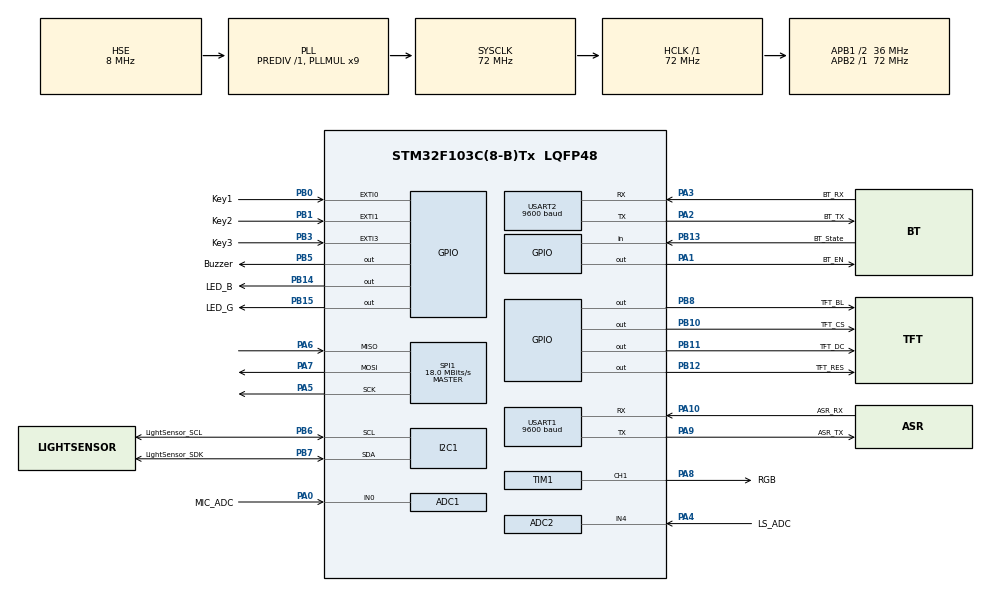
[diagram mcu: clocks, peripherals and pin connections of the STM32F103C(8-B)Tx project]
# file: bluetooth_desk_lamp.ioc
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ADC1.Channel-0\#ChannelRegularConversion=ADC_CHANNEL_0
ADC1.ContinuousConvMode=DISABLE
ADC1.ExternalTrigConv=ADC_EXTERNALTRIGCONV_T3_TRGO
ADC1.NbrOfConversion=1
ADC1.NbrOfConversionFlag=1
ADC1.Rank-0\#ChannelRegularConversion=1
ADC1.SamplingTime-0\#ChannelRegularConversion=ADC_SAMPLETIME_239CYCLES_5
ADC1.master=1
ADC2.Channel-0\#ChannelRegularConversion=ADC_CHANNEL_4
ADC2.ContinuousConvMode=ENABLE
ADC2.NbrOfConversionFlag=1
ADC2.Rank-0\#ChannelRegularConversion=1
ADC2.SamplingTime-0\#ChannelRegularConversion=ADC_SAMPLETIME_1CYCLE_5
Dma.ADC1.0.Direction=DMA_PERIPH_TO_MEMORY
Dma.ADC1.0.Instance=DMA1_Channel1
Dma.ADC1.0.MemDataAlignment=DMA_MDATAALIGN_HALFWORD
Dma.ADC1.0.MemInc=DMA_MINC_ENABLE
Dma.ADC1.0.Mode=DMA_CIRCULAR
Dma.ADC1.0.PeriphDataAlignment=DMA_PDATAALIGN_HALFWORD
Dma.ADC1.0.PeriphInc=DMA_PINC_DISABLE
Dma.ADC1.0.Priority=DMA_PRIORITY_MEDIUM
Dma.Request0=ADC1
Dma.Request1=USART1_RX
Dma.Request2=USART1_TX
Dma.Request3=TIM1_CH1
Dma.TIM1_CH1.3.Direction=DMA_MEMORY_TO_PERIPH
Dma.TIM1_CH1.3.Instance=DMA1_Channel2
Dma.TIM1_CH1.3.MemDataAlignment=DMA_MDATAALIGN_HALFWORD
Dma.TIM1_CH1.3.MemInc=DMA_MINC_ENABLE
Dma.TIM1_CH1.3.Mode=DMA_NORMAL
Dma.TIM1_CH1.3.PeriphDataAlignment=DMA_PDATAALIGN_HALFWORD
Dma.TIM1_CH1.3.PeriphInc=DMA_PINC_DISABLE
Dma.TIM1_CH1.3.Priority=DMA_PRIORITY_LOW
Dma.USART1_RX.1.Direction=DMA_PERIPH_TO_MEMORY
Dma.USART1_RX.1.Instance=DMA1_Channel5
Dma.USART1_RX.1.MemDataAlignment=DMA_MDATAALIGN_BYTE
Dma.USART1_RX.1.MemInc=DMA_MINC_ENABLE
Dma.USART1_RX.1.Mode=DMA_CIRCULAR
Dma.USART1_RX.1.PeriphDataAlignment=DMA_PDATAALIGN_BYTE
Dma.USART1_RX.1.PeriphInc=DMA_PINC_DISABLE
Dma.USART1_RX.1.Priority=DMA_PRIORITY_HIGH
Dma.USART1_TX.2.Direction=DMA_MEMORY_TO_PERIPH
Dma.USART1_TX.2.Instance=DMA1_Channel4
Dma.USART1_TX.2.MemDataAlignment=DMA_MDATAALIGN_BYTE
Dma.USART1_TX.2.MemInc=DMA_MINC_ENABLE
Dma.USART1_TX.2.Mode=DMA_NORMAL
Dma.USART1_TX.2.PeriphDataAlignment=DMA_PDATAALIGN_BYTE
Dma.USART1_TX.2.PeriphInc=DMA_PINC_DISABLE
Dma.USART1_TX.2.Priority=DMA_PRIORITY_MEDIUM
Mcu.Family=STM32F1
Mcu.Name=STM32F103C(8-B)Tx
Mcu.Package=LQFP48
NVIC.DMA1_Channel1_IRQn=true\:0\:0\:false\:false\:true\:false\:true\:true
NVIC.DMA1_Channel2_IRQn=true\:0\:0\:false\:false\:true\:false\:true\:true
NVIC.DMA1_Channel4_IRQn=true\:0\:0\:false\:false\:true\:false\:true\:true
NVIC.DMA1_Channel5_IRQn=true\:0\:0\:false\:false\:true\:false\:true\:true
NVIC.EXTI0_IRQn=true\:0\:0\:false\:false\:true\:true\:true\:true
NVIC.EXTI1_IRQn=true\:0\:0\:false\:false\:true\:true\:true\:true
NVIC.EXTI3_IRQn=true\:0\:0\:false\:false\:true\:true\:true\:true
NVIC.PriorityGroup=NVIC_PRIORITYGROUP_4
NVIC.USART1_IRQn=true\:0\:0\:false\:false\:true\:true\:true\:true
NVIC.USART2_IRQn=true\:0\:0\:false\:false\:true\:true\:true\:true
PA0-WKUP.GPIO_Label=MIC_ADC
PA0-WKUP.Signal=ADCx_IN0
PA1.GPIO_Label=BT_EN
PA1.Signal=GPIO_Output
PA10.GPIO_Label=ASR_RX
PA10.Mode=Asynchronous
PA10.Signal=USART1_RX
PA13.Mode=Serial_Wire
PA13.Signal=SYS_JTMS-SWDIO
PA14.Mode=Serial_Wire
PA14.Signal=SYS_JTCK-SWCLK
PA2.GPIO_Label=BT_TX
PA2.Mode=Asynchronous
PA2.Signal=USART2_TX
PA3.GPIO_Label=BT_RX
PA3.Mode=Asynchronous
PA3.Signal=USART2_RX
PA4.GPIO_Label=LS_ADC
PA4.Signal=ADCx_IN4
PA5.Mode=Full_Duplex_Master
PA5.Signal=SPI1_SCK
PA6.Mode=Full_Duplex_Master
PA6.Signal=SPI1_MISO
PA7.Mode=Full_Duplex_Master
PA7.Signal=SPI1_MOSI
PA8.GPIO_Label=RGB
PA8.Signal=S_TIM1_CH1
PA9.GPIO_Label=ASR_TX
PA9.Mode=Asynchronous
PA9.Signal=USART1_TX
PB0.GPIO_Label=Key1
PB0.GPIO_ModeDefaultEXTI=GPIO_MODE_IT_FALLING
PB0.GPIO_PuPd=GPIO_PULLUP
PB0.Signal=GPXTI0
PB1.GPIO_Label=Key2
PB1.GPIO_ModeDefaultEXTI=GPIO_MODE_IT_FALLING
PB1.GPIO_PuPd=GPIO_PULLUP
PB1.Signal=GPXTI1
PB10.GPIO_Label=TFT_CS
PB10.PinState=GPIO_PIN_SET
PB10.Signal=GPIO_Output
PB11.GPIO_Label=TFT_DC
PB11.Signal=GPIO_Output
PB12.GPIO_Label=TFT_RES
PB12.PinState=GPIO_PIN_SET
PB12.Signal=GPIO_Output
PB13.GPIO_Label=BT_State
PB13.Signal=GPIO_Input
PB14.GPIO_Label=LED_B
PB14.Signal=GPIO_Output
PB15.GPIO_Label=LED_G
PB15.Signal=GPIO_Output
PB3.GPIO_Label=Key3
PB3.GPIO_ModeDefaultEXTI=GPIO_MODE_IT_FALLING
PB3.GPIO_PuPd=GPIO_PULLUP
PB3.Signal=GPXTI3
PB5.GPIO_Label=Buzzer
PB5.Signal=GPIO_Output
PB6.GPIO_Label=LightSensor_SCL
PB6.Mode=I2C
PB6.Signal=I2C1_SCL
PB7.GPIO_Label=LightSensor_SDK
PB7.Mode=I2C
PB7.Signal=I2C1_SDA
PB8.GPIO_Label=TFT_BL
PB8.Signal=GPIO_Output
PD0-OSC_IN.Mode=HSE-External-Oscillator
PD0-OSC_IN.Signal=RCC_OSC_IN
PD1-OSC_OUT.Mode=HSE-External-Oscillator
PD1-OSC_OUT.Signal=RCC_OSC_OUT
ProjectManager.HeapSize=0x200
ProjectManager.StackSize=0x400
ProjectManager.TargetToolchain=MDK-ARM V5.32
RCC.ADCPresc=RCC_ADCPCLK2_DIV6
RCC.AHBFreq_Value=72000000
RCC.APB1CLKDivider=RCC_HCLK_DIV2
RCC.APB1Freq_Value=36000000
RCC.APB1TimFreq_Value=72000000
RCC.APB2Freq_Value=72000000
RCC.APB2TimFreq_Value=72000000
RCC.HCLKFreq_Value=72000000
RCC.PLLMUL=RCC_PLL_MUL9
RCC.PLLSourceVirtual=RCC_PLLSOURCE_HSE
RCC.SYSCLKFreq_VALUE=72000000
RCC.SYSCLKSource=RCC_SYSCLKSOURCE_PLLCLK
RCC.USBFreq_Value=72000000
SH.ADCx_IN0.0=ADC1_IN0,IN0
SH.ADCx_IN4.0=ADC2_IN4,IN4
SH.S_TIM1_CH1.0=TIM1_CH1,PWM Generation1 CH1
SPI1.BaudRatePrescaler=SPI_BAUDRATEPRESCALER_4
SPI1.CalculateBaudRate=18.0 MBits/s
SPI1.Direction=SPI_DIRECTION_2LINES
SPI1.Mode=SPI_MODE_MASTER
SPI1.VirtualType=VM_MASTER
TIM1.Channel-PWM\ Generation1\ CH1=TIM_CHANNEL_1
TIM1.Period=89
TIM3.Period=99
TIM3.Prescaler=71
TIM3.TIM_MasterOutputTrigger=TIM_TRGO_UPDATE
TIM3.TIM_MasterSlaveMode=TIM_MASTERSLAVEMODE_ENABLE
USART1.BaudRate=9600
USART1.VirtualMode=VM_ASYNC
USART2.BaudRate=9600
USART2.VirtualMode=VM_ASYNC
VP_TIM1_VS_ClockSourceINT.Mode=Internal
VP_TIM3_VS_ClockSourceINT.Mode=Internal
board=custom

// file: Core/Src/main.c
/* USER CODE BEGIN Header */
/**
  ******************************************************************************
  * @file           : main.c
  * @brief          : Main program body
  ******************************************************************************
  * @attention
  *
  * Copyright (c) 2026 STMicroelectronics.
  * All rights reserved.
  *
  * This software is licensed under terms that can be found in the LICENSE file
  * in the root directory of this software component.
  * If no LICENSE file comes with this software, it is provided AS-IS.
  *
  ******************************************************************************
  */
/* USER CODE END Header */
#include "main.h"
#include "adc.h"
#include "dma.h"
#include "i2c.h"
#include "spi.h"
#include "tim.h"
#include "usart.h"
#include "gpio.h"

/* USER CODE BEGIN Includes */
#include "app_manager.h"
/* USER CODE END Includes */

void SystemClock_Config(void);

int main(void)
{

  /* MCU Configuration--------------------------------------------------------*/

  /* Reset of all peripherals, Initializes the Flash interface and the Systick. */
  HAL_Init();

  /* Configure the system clock */
  SystemClock_Config();

  /* Initialize all configured peripherals */
  MX_GPIO_Init();
  MX_DMA_Init();
  MX_I2C1_Init();
  MX_SPI1_Init();
  MX_USART1_UART_Init();
  MX_USART2_UART_Init();
  MX_ADC1_Init();
  MX_TIM3_Init();
  MX_TIM1_Init();
  MX_ADC2_Init();
  /* USER CODE BEGIN 2 */

  system_Init();

  // system_PowerOn(); // 正式时不要执行这句

  /* USER CODE END 2 */

  /* Infinite loop */
  /* USER CODE BEGIN WHILE */
  while (1)
  {
    system_Run();

    /* USER CODE END WHILE */

  }
}

void SystemClock_Config(void)
{
  RCC_OscInitTypeDef RCC_OscInitStruct = {0};
  RCC_ClkInitTypeDef RCC_ClkInitStruct = {0};
  RCC_PeriphCLKInitTypeDef PeriphClkInit = {0};

  /** Initializes the RCC Oscillators according to the specified parameters
  * in the RCC_OscInitTypeDef structure.
  */
  RCC_OscInitStruct.OscillatorType = RCC_OSCILLATORTYPE_HSE;
  RCC_OscInitStruct.HSEState = RCC_HSE_ON;
  RCC_OscInitStruct.HSEPredivValue = RCC_HSE_PREDIV_DIV1;
  RCC_OscInitStruct.HSIState = RCC_HSI_ON;
  RCC_OscInitStruct.PLL.PLLState = RCC_PLL_ON;
  RCC_OscInitStruct.PLL.PLLSource = RCC_PLLSOURCE_HSE;
  RCC_OscInitStruct.PLL.PLLMUL = RCC_PLL_MUL9;
  if (HAL_RCC_OscConfig(&RCC_OscInitStruct) != HAL_OK)
  {
    Error_Handler();
  }

  /** Initializes the CPU, AHB and APB buses clocks
  */
  RCC_ClkInitStruct.ClockType = RCC_CLOCKTYPE_HCLK|RCC_CLOCKTYPE_SYSCLK
                              |RCC_CLOCKTYPE_PCLK1|RCC_CLOCKTYPE_PCLK2;
  RCC_ClkInitStruct.SYSCLKSource = RCC_SYSCLKSOURCE_PLLCLK;
  RCC_ClkInitStruct.AHBCLKDivider = RCC_SYSCLK_DIV1;
  RCC_ClkInitStruct.APB1CLKDivider = RCC_HCLK_DIV2;
  RCC_ClkInitStruct.APB2CLKDivider = RCC_HCLK_DIV1;

  if (HAL_RCC_ClockConfig(&RCC_ClkInitStruct, FLASH_LATENCY_2) != HAL_OK)
  {
    Error_Handler();
  }
  PeriphClkInit.PeriphClockSelection = RCC_PERIPHCLK_ADC;
  PeriphClkInit.AdcClockSelection = RCC_ADCPCLK2_DIV6;
  if (HAL_RCCEx_PeriphCLKConfig(&PeriphClkInit) != HAL_OK)
  {
    Error_Handler();
  }
}

void Error_Handler(void)
{
  __disable_irq();
  while (1)
  {
  }
}
